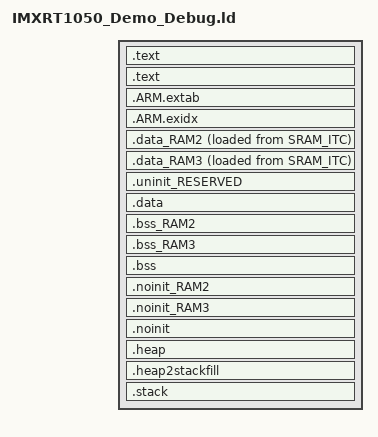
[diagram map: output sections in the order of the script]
/*
 * GENERATED FILE - DO NOT EDIT
 * Copyright (c) 2008-2013 Code Red Technologies Ltd,
 * Copyright 2015, 2018-2019 NXP
 * (c) NXP Semiconductors 2013-2021
 * Generated linker script file for MIMXRT1052xxxxB
 * Created from linkscript.ldt by FMCreateLinkLibraries
 * Using Freemarker v2.3.23
 * MCUXpresso IDE v11.2.1 [Build 4149] [2020-10-07] on 2021-3-23 14:22:54
 */

INCLUDE "IMXRT1050_Demo_Debug_library.ld"
INCLUDE "IMXRT1050_Demo_Debug_memory.ld"

ENTRY(ResetISR)

SECTIONS
{
     /* MAIN TEXT SECTION */
    .text : ALIGN(4)
    {
        FILL(0xff)
        __vectors_start__ = ABSOLUTE(.) ;
        KEEP(*(.isr_vector))
        /* Global Section Table */
        . = ALIGN(4) ;
        __section_table_start = .;
        __data_section_table = .;
        LONG(LOADADDR(.data));
        LONG(    ADDR(.data));
        LONG(  SIZEOF(.data));
        LONG(LOADADDR(.data_RAM2));
        LONG(    ADDR(.data_RAM2));
        LONG(  SIZEOF(.data_RAM2));
        LONG(LOADADDR(.data_RAM3));
        LONG(    ADDR(.data_RAM3));
        LONG(  SIZEOF(.data_RAM3));
        __data_section_table_end = .;
        __bss_section_table = .;
        LONG(    ADDR(.bss));
        LONG(  SIZEOF(.bss));
        LONG(    ADDR(.bss_RAM2));
        LONG(  SIZEOF(.bss_RAM2));
        LONG(    ADDR(.bss_RAM3));
        LONG(  SIZEOF(.bss_RAM3));
        __bss_section_table_end = .;
        __section_table_end = . ;
        /* End of Global Section Table */

        *(.after_vectors*)

    } > SRAM_ITC

    .text : ALIGN(4)
    {
       *(.text*)
       *(.rodata .rodata.* .constdata .constdata.*)
       . = ALIGN(4);
    } > SRAM_ITC
    /*
     * for exception handling/unwind - some Newlib functions (in common
     * with C++ and STDC++) use this.
     */
    .ARM.extab : ALIGN(4)
    {
        *(.ARM.extab* .gnu.linkonce.armextab.*)
    } > SRAM_ITC

    .ARM.exidx : ALIGN(4)
    {
        __exidx_start = .;
        *(.ARM.exidx* .gnu.linkonce.armexidx.*)
        __exidx_end = .;
    } > SRAM_ITC
 
    _etext = .;
        
    /* DATA section for SRAM_DTC */

    .data_RAM2 : ALIGN(4)
    {
        FILL(0xff)
        PROVIDE(__start_data_RAM2 = .) ;
        PROVIDE(__start_data_SRAM_DTC = .) ;
        *(.ramfunc.$RAM2)
        *(.ramfunc.$SRAM_DTC)
        *(.data.$RAM2)
        *(.data.$SRAM_DTC)
        *(.data.$RAM2.*)
        *(.data.$SRAM_DTC.*)
        . = ALIGN(4) ;
        PROVIDE(__end_data_RAM2 = .) ;
        PROVIDE(__end_data_SRAM_DTC = .) ;
     } > SRAM_DTC AT>SRAM_ITC

    /* DATA section for SRAM_OC */

    .data_RAM3 : ALIGN(4)
    {
        FILL(0xff)
        PROVIDE(__start_data_RAM3 = .) ;
        PROVIDE(__start_data_SRAM_OC = .) ;
        *(.ramfunc.$RAM3)
        *(.ramfunc.$SRAM_OC)
        *(.data.$RAM3)
        *(.data.$SRAM_OC)
        *(.data.$RAM3.*)
        *(.data.$SRAM_OC.*)
        . = ALIGN(4) ;
        PROVIDE(__end_data_RAM3 = .) ;
        PROVIDE(__end_data_SRAM_OC = .) ;
     } > SRAM_OC AT>SRAM_ITC

    /* MAIN DATA SECTION */
    .uninit_RESERVED (NOLOAD) : ALIGN(4)
    {
        _start_uninit_RESERVED = .;
        KEEP(*(.bss.$RESERVED*))
       . = ALIGN(4) ;
        _end_uninit_RESERVED = .;
    } > SRAM_ITC AT> SRAM_ITC

    /* Main DATA section (SRAM_ITC) */
    .data : ALIGN(4)
    {
       FILL(0xff)
       _data = . ;
       PROVIDE(__start_data_RAM = .) ;
       PROVIDE(__start_data_SRAM_ITC = .) ;
       *(vtable)
       *(.ramfunc*)
       KEEP(*(CodeQuickAccess))
       KEEP(*(DataQuickAccess))
       *(RamFunction)
       *(.data*)
       . = ALIGN(4) ;
       _edata = . ;
       PROVIDE(__end_data_RAM = .) ;
       PROVIDE(__end_data_SRAM_ITC = .) ;
    } > SRAM_ITC AT>SRAM_ITC

    /* BSS section for SRAM_DTC */
    .bss_RAM2 : ALIGN(4)
    {
       PROVIDE(__start_bss_RAM2 = .) ;
       PROVIDE(__start_bss_SRAM_DTC = .) ;
       *(.bss.$RAM2)
       *(.bss.$SRAM_DTC)
       *(.bss.$RAM2.*)
       *(.bss.$SRAM_DTC.*)
       . = ALIGN (. != 0 ? 4 : 1) ; /* avoid empty segment */
       PROVIDE(__end_bss_RAM2 = .) ;
       PROVIDE(__end_bss_SRAM_DTC = .) ;
    } > SRAM_DTC AT> SRAM_DTC

    /* BSS section for SRAM_OC */
    .bss_RAM3 : ALIGN(4)
    {
       PROVIDE(__start_bss_RAM3 = .) ;
       PROVIDE(__start_bss_SRAM_OC = .) ;
       *(.bss.$RAM3)
       *(.bss.$SRAM_OC)
       *(.bss.$RAM3.*)
       *(.bss.$SRAM_OC.*)
       . = ALIGN (. != 0 ? 4 : 1) ; /* avoid empty segment */
       PROVIDE(__end_bss_RAM3 = .) ;
       PROVIDE(__end_bss_SRAM_OC = .) ;
    } > SRAM_OC AT> SRAM_OC

    /* MAIN BSS SECTION */
    .bss : ALIGN(4)
    {
        _bss = .;
        PROVIDE(__start_bss_RAM = .) ;
        PROVIDE(__start_bss_SRAM_ITC = .) ;
        *(.bss*)
        *(COMMON)
        . = ALIGN(4) ;
        _ebss = .;
        PROVIDE(__end_bss_RAM = .) ;
        PROVIDE(__end_bss_SRAM_ITC = .) ;
        PROVIDE(end = .);
    } > SRAM_ITC AT> SRAM_ITC

    /* NOINIT section for SRAM_DTC */
    .noinit_RAM2 (NOLOAD) : ALIGN(4)
    {
       PROVIDE(__start_noinit_RAM2 = .) ;
       PROVIDE(__start_noinit_SRAM_DTC = .) ;
       *(.noinit.$RAM2)
       *(.noinit.$SRAM_DTC)
       *(.noinit.$RAM2.*)
       *(.noinit.$SRAM_DTC.*)
       . = ALIGN(4) ;
       PROVIDE(__end_noinit_RAM2 = .) ;
       PROVIDE(__end_noinit_SRAM_DTC = .) ;
    } > SRAM_DTC AT> SRAM_DTC

    /* NOINIT section for SRAM_OC */
    .noinit_RAM3 (NOLOAD) : ALIGN(4)
    {
       PROVIDE(__start_noinit_RAM3 = .) ;
       PROVIDE(__start_noinit_SRAM_OC = .) ;
       *(.noinit.$RAM3)
       *(.noinit.$SRAM_OC)
       *(.noinit.$RAM3.*)
       *(.noinit.$SRAM_OC.*)
       . = ALIGN(4) ;
       PROVIDE(__end_noinit_RAM3 = .) ;
       PROVIDE(__end_noinit_SRAM_OC = .) ;
    } > SRAM_OC AT> SRAM_OC

    /* DEFAULT NOINIT SECTION */
    .noinit (NOLOAD): ALIGN(4)
    {
        _noinit = .;
        PROVIDE(__start_noinit_RAM = .) ;
        PROVIDE(__start_noinit_SRAM_ITC = .) ;
        *(.noinit*)
         . = ALIGN(4) ;
        _end_noinit = .;
       PROVIDE(__end_noinit_RAM = .) ;
       PROVIDE(__end_noinit_SRAM_ITC = .) ;        
    } > SRAM_ITC AT> SRAM_ITC

    /* Reserve and place Heap within memory map */
    _HeapSize = 0x1000;
    .heap :  ALIGN(4)
    {
        _pvHeapStart = .;
        . += _HeapSize;
        . = ALIGN(4);
        _pvHeapLimit = .;
    } > SRAM_ITC

     _StackSize = 0x1000;
     /* Reserve space in memory for Stack */
    .heap2stackfill  :
    {
        . += _StackSize;
    } > SRAM_ITC
    /* Locate actual Stack in memory map */
    .stack ORIGIN(SRAM_ITC) + LENGTH(SRAM_ITC) - _StackSize - 0:  ALIGN(4)
    {
        _vStackBase = .;
        . = ALIGN(4);
        _vStackTop = . + _StackSize;
    } > SRAM_ITC

    /* Provide basic symbols giving location and size of main text
     * block, including initial values of RW data sections. Note that
     * these will need extending to give a complete picture with
     * complex images (e.g multiple Flash banks).
     */
    _image_start = LOADADDR(.text);
    _image_end = LOADADDR(.data) + SIZEOF(.data);
    _image_size = _image_end - _image_start;
}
